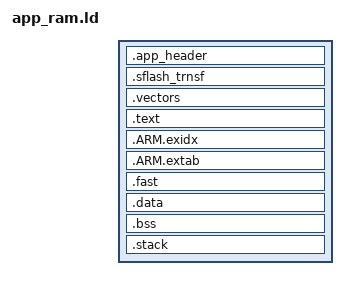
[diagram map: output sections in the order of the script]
/*
 * Copyright (c) 2015 Broadcom
 * All rights reserved.
 *
 * Redistribution and use in source and binary forms, with or without modification,
 * are permitted provided that the following conditions are met:
 *
 * 1. Redistributions of source code must retain the above copyright notice, this
 * list of conditions and the following disclaimer.
 *
 * 2. Redistributions in binary form must reproduce the above copyright notice, this
 * list of conditions and the following disclaimer in the documentation and/or
 * other materials provided with the distribution.
 *
 * 3. Neither the name of Broadcom nor the names of other contributors to this
 * software may be used to endorse or promote products derived from this software
 * without specific prior written permission.
 *
 * 4. This software may not be used as a standalone product, and may only be used as
 * incorporated in your product or device that incorporates Broadcom wireless connectivity
 * products and solely for the purpose of enabling the functionalities of such Broadcom products.
 *
 *
 * THIS SOFTWARE IS PROVIDED BY THE COPYRIGHT HOLDERS AND CONTRIBUTORS "AS IS" AND
 * ANY WARRANTIES OF ANY KIND, EXPRESS OR IMPLIED, INCLUDING, BUT NOT LIMITED TO, THE IMPLIED
 * WARRANTIES OF MERCHANTABILITY, FITNESS FOR A PARTICULAR PURPOSE AND NON-INFRINGEMENT, ARE
 * DISCLAIMED. IN NO EVENT SHALL THE COPYRIGHT HOLDER OR CONTRIBUTORS BE LIABLE FOR
 * ANY DIRECT, INDIRECT, INCIDENTAL, SPECIAL, EXEMPLARY, OR CONSEQUENTIAL DAMAGES
 * (INCLUDING, BUT NOT LIMITED TO, PROCUREMENT OF SUBSTITUTE GOODS OR SERVICES;
 * LOSS OF USE, DATA, OR PROFITS; OR BUSINESS INTERRUPTION) HOWEVER CAUSED AND ON
 * ANY THEORY OF LIABILITY, WHETHER IN CONTRACT, STRICT LIABILITY, OR TORT
 * (INCLUDING NEGLIGENCE OR OTHERWISE) ARISING IN ANY WAY OUT OF THE USE OF THIS
 * SOFTWARE, EVEN IF ADVISED OF THE POSSIBILITY OF SUCH DAMAGE.
 */

reset_handler = _start;

ENTRY( _start );

/* Include memory map */
INCLUDE memory_ram.ld

SECTIONS
{

    .app_header :
    {
        bootloader_app_header_location = .;
        KEEP(*(*.bootloader_app_header));
    }>OTA_HDR  AT> OTA_HDR


    /* Data transfer area for serial flash writing app  - at start of memory */
    .sflash_trnsf :
    {
        KEEP(*(*.data_config))
        KEEP(*(*.data_transfer))
    }>SRAM AT> SRAM


    .vectors :
    {
        . = ALIGN(512);
        link_interrupt_vectors_location = .;
        KEEP(*(*.interrupt_vector_table))
    }>SRAM AT> SRAM

    .text :
    {
        . = ALIGN(4);

        link_code_location = .;
        KEEP(*(.text.irq ))
        *(.text .text.* .gnu.linkonce.t.*)
        link_code_end = .;

        . = ALIGN(0x4);

        link_const_variable_data_location = .;
        wifi_firmware_image_location = .;
        *(.rodata.wifi_firmware_image)
        wifi_firmware_image_end = .;
        *(.rodata .rodata.* .gnu.linkonce.r.*)
        link_const_variable_data_end = .;

        . = ALIGN(0x4);

        link_constructors_location = .;
        KEEP(*(.preinit_array))
        KEEP(*(.init_array))
        KEEP (*crtbegin.o(.ctors))
        KEEP (*(EXCLUDE_FILE (*crtend.o) .ctors))
        KEEP (*(SORT(.ctors.*)))
        KEEP (*crtend.o(.ctors))
        link_constructors_end = .;

        . = ALIGN(0x4);

        link_destructors_location = .;
        KEEP (*crtbegin.o(.dtors))
        KEEP (*(EXCLUDE_FILE (*crtend.o) .dtors))
        KEEP (*(SORT(.dtors.*)))
        KEEP (*crtend.o(.dtors))
        link_destructors_end = .;

        . = ALIGN(16);

    }>SRAM AT> SRAM

    /*
     * The .ARM.exidx and .ARM.exidx sections are used for C++ exception handling.
     * It is located here for completeness. Bare-metal ARM projects
     * typically cannot afford the overhead associated with C++
     * exceptions handling.
     */
    .ARM.exidx :
    {
        __exidx_start = ALIGN(4);
        *(.ARM.exidx* .gnu.linkonce.armexidx.*)
        __exidx_end = .;
    } >SRAM AT> SRAM

    .ARM.extab :
    {
        __extab_start = ALIGN(4);
        *(.ARM.extab*)
        __extab_end = .;
    } > SRAM  AT> SRAM

    .fast : /* This section contains code that is run from RAM after being loaded from flash - functions can be put in this section with the C attribute: __attribute__ ((section (".fast"))) */
    {
        link_run_from_ram_code_flash_location = LOADADDR( .fast ); /* This is the location in flash of the code */
        link_run_from_ram_code_ram_location = .;
        *(.fast .fast.* .text.fastcode)
        link_run_from_ram_code_ram_end = .;
    }>SRAM AT> SRAM

    .data : /* Contains the non-zero initialised global variables */
    {
        link_global_data_initial_values = LOADADDR( .data ); /* This is the location in flash of the initial values of global variables */
        link_global_data_start = .;
        *(.data*)
        link_global_data_end = .;
        . = ALIGN(., 4);
    }>SRAM AT> SRAM


    .bss : /* Zero initialised memory used for zero initialised variables */
    {
        link_bss_location = ALIGN(., 4);
        *(.bss*)
        *(COMMON)
        link_bss_end = .;
        . = ALIGN(., 4);
    }> SRAM AT>SRAM


    .stack : /* Contains the initial stack */
    {
        link_stack_location = ALIGN(., 4);
        *(.stack)
        . = ALIGN(MAX(link_stack_location + __STACKSIZE__ , .), 4);
        link_stack_end = .;
    }> SRAM AT>SRAM

    /DISCARD/ :
    {
        *(.ARM.attributes*)
        *(.comment)
        *(.init)
        *(.preinit)
        *(.fini)
        *(.fini_array)
        *(.ARM.exidx*)
        *(.gnu.linkonce.armexidx.*)
        *(.eh_frame_hdr)
        *(.eh_frame)
        *(.gnu.linkonce.armextab.*)
        *(.v4_bx)
        *(.vfp11_veneer)
        *(.gcc_except_table)
        *(.eh_frame_hdr)
        *(.eh_frame)
        *(.glue*)
    }

}

/* Declare libc Heap to start at end of allocated RAM */

PROVIDE( _heap = link_stack_end );

/* End of the heap is top of RAM, aligned 8 byte */

PROVIDE( _eheap = ALIGN( ORIGIN( SRAM ) + LENGTH( SRAM ) - 8, 8 ) );
PROVIDE( total_app_image_size = LOADADDR( .data ) - ORIGIN( SRAM ) + link_global_data_end - link_global_data_start );
PROVIDE( wifi_firmware_image_size_from_link = wifi_firmware_image_end - wifi_firmware_image_location );
PROVIDE( vectors_offset = link_interrupt_vectors_location - bootloader_app_header_location );

/* ThreadX aliases */
PROVIDE( __RAM_segment_used_end__ = link_stack_end );
PROVIDE( __tx_free_memory_start = link_stack_end );
PROVIDE( __tx_vectors = link_interrupt_vectors_location );

PROVIDE( wifi_firmware_image = 0 );
PROVIDE( bootloader_api_addr_loc     = 0x08000200);



